# STM32WB55x register map
File version: 1.0
CPU: CM4 r0p1, little endian, 4 interrupt priority bits
Registers are 32-bit, read-write, reset 0x0 unless marked. A register's access mark holds for its fields unless they carry their own. Offsets are from the block's base; [hi:lo] are bit positions; {n}, {i} and the like mark numbered series; 'fields as' and 'values as' point back to an identical list.

## IWDG
Base 0x40003000
0x00 KR
  [15:0] KEY
0x04 PR
  [2:0] PR
0x08 RLR
  [11:0] RL
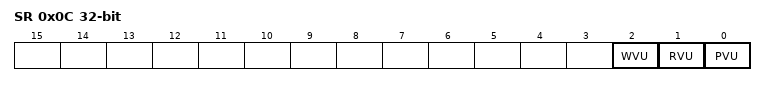
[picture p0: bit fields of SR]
0x0C SR
  [2] WVU, [1] RVU, [0] PVU
0x10 WINR
  [11:0] WIN

## WWDG
Base 0x40002C00
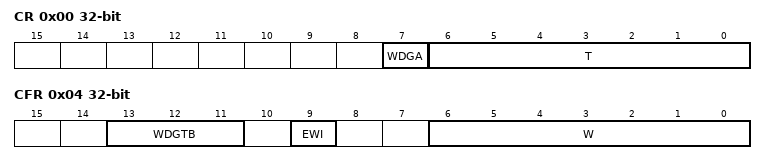
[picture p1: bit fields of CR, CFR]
0x00 CR
  [7] WDGA, [6:0] T
0x04 CFR
  [13:11] WDGTB, [9] EWI, [6:0] W
0x08 SR
  [0] EWIF

## USB_FS
Base 0x40006800
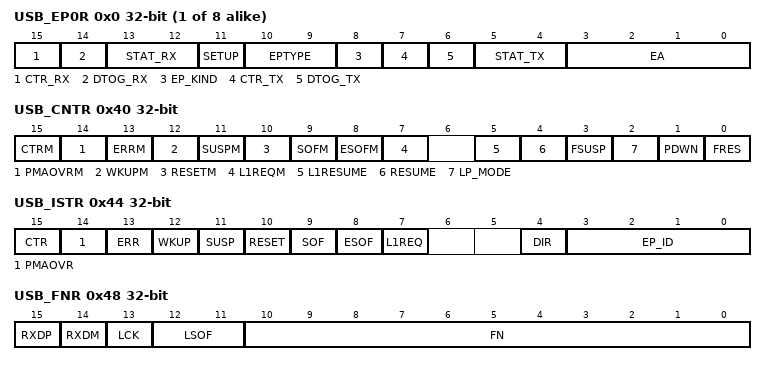
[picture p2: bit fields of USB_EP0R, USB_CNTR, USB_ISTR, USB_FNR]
{0x0+4i} USB_EP{i}R (i=0..7)
  [15] CTR_RX, [14] DTOG_RX, [13:12] STAT_RX, [11] SETUP, [10:9] EPTYPE, [8] EP_KIND, [7] CTR_TX, [6] DTOG_TX, [5:4] STAT_TX, [3:0] EA
0x40 USB_CNTR
  [15] CTRM, [14] PMAOVRM, [13] ERRM, [12] WKUPM, [11] SUSPM, [10] RESETM, [9] SOFM, [8] ESOFM, [7] L1REQM, [5] L1RESUME, [4] RESUME, [3] FSUSP, [2] LP_MODE, [1] PDWN, [0] FRES
0x44 USB_ISTR
  [15] CTR, [14] PMAOVR, [13] ERR, [12] WKUP, [11] SUSP, [10] RESET, [9] SOF, [8] ESOF, [7] L1REQ, [4] DIR, [3:0] EP_ID
0x48 USB_FNR
  [15] RXDP, [14] RXDM, [13] LCK, [12:11] LSOF, [10:0] FN
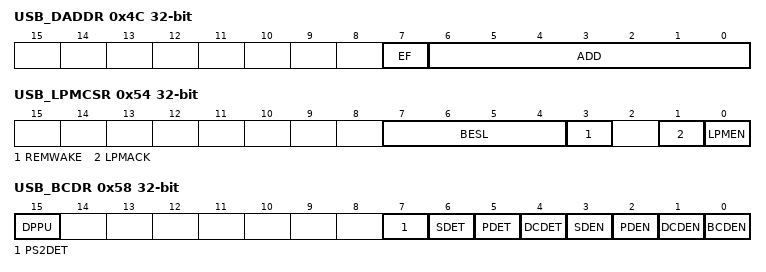
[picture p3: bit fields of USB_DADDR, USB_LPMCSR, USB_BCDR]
0x4C USB_DADDR
  [7] EF, [6:0] ADD
0x50 USB_BTABLE
  [15:3] BTABLE
0x54 USB_LPMCSR
  [7:4] BESL, [3] REMWAKE, [1] LPMACK, [0] LPMEN
0x58 USB_BCDR
  [15] DPPU, [7] PS2DET, [6] SDET, [5] PDET, [4] DCDET, [3] SDEN, [2] PDEN, [1] DCDEN, [0] BCDEN

## USART1
Base 0x40013800
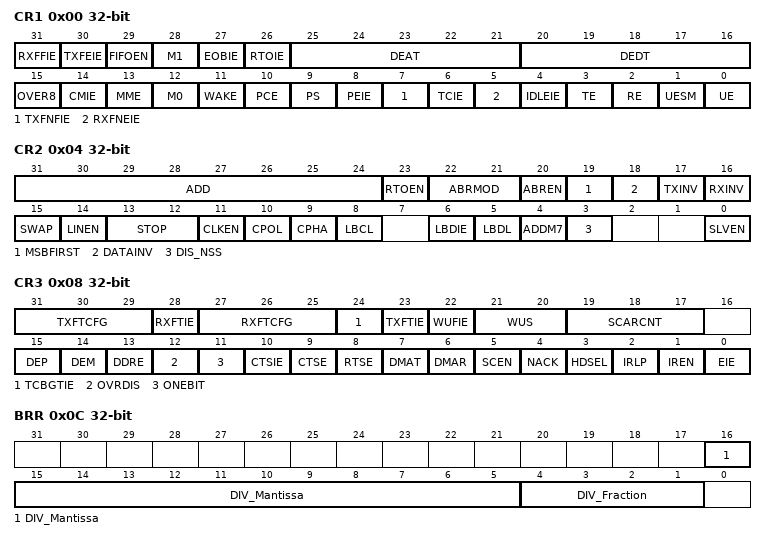
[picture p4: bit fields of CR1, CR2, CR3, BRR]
0x00 CR1
  [31] RXFFIE, [30] TXFEIE, [29] FIFOEN, [28] M1, [27] EOBIE, [26] RTOIE, [25:21] DEAT, [20:16] DEDT, [15] OVER8, [14] CMIE, [13] MME, [12] M0, [11] WAKE, [10] PCE, [9] PS, [8] PEIE, [7] TXFNFIE, [6] TCIE, [5] RXFNEIE, [4] IDLEIE, [3] TE, [2] RE, [1] UESM, [0] UE
0x04 CR2
  [31:24] ADD, [23] RTOEN, [22:21] ABRMOD, [20] ABREN, [19] MSBFIRST, [18] DATAINV, [17] TXINV, [16] RXINV, [15] SWAP, [14] LINEN, [13:12] STOP, [11] CLKEN, [10] CPOL, [9] CPHA, [8] LBCL, [6] LBDIE, [5] LBDL, [4] ADDM7, [3] DIS_NSS, [0] SLVEN
0x08 CR3
  [31:29] TXFTCFG, [28] RXFTIE, [27:25] RXFTCFG, [24] TCBGTIE, [23] TXFTIE, [22] WUFIE, [21:20] WUS, [19:17] SCARCNT, [15] DEP, [14] DEM, [13] DDRE, [12] OVRDIS, [11] ONEBIT, [10] CTSIE, [9] CTSE, [8] RTSE, [7] DMAT, [6] DMAR, [5] SCEN, [4] NACK, [3] HDSEL, [2] IRLP, [1] IREN, [0] EIE
0x0C BRR
  [16:5] DIV_Mantissa, [4:1] DIV_Fraction
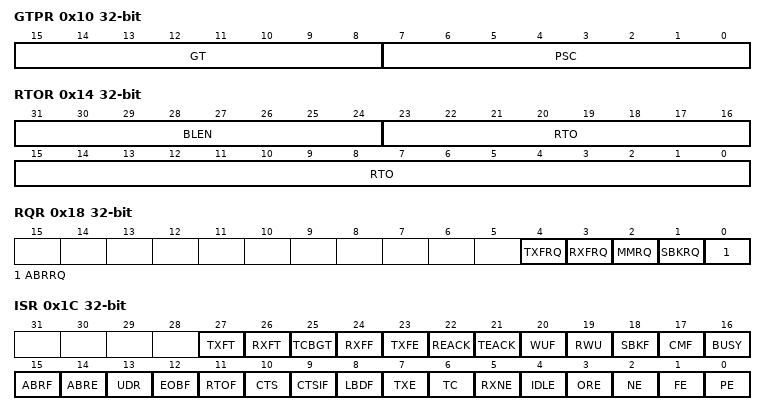
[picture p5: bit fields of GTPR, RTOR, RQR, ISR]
0x10 GTPR
  [15:8] GT, [7:0] PSC
0x14 RTOR
  [31:24] BLEN, [23:0] RTO
0x18 RQR
  [4] TXFRQ, [3] RXFRQ, [2] MMRQ, [1] SBKRQ, [0] ABRRQ
0x1C ISR
  [27] TXFT, [26] RXFT, [25] TCBGT, [24] RXFF, [23] TXFE, [22] REACK, [21] TEACK, [20] WUF, [19] RWU, [18] SBKF, [17] CMF, [16] BUSY, [15] ABRF, [14] ABRE, [13] UDR, [12] EOBF, [11] RTOF, [10] CTS, [9] CTSIF, [8] LBDF, [7] TXE, [6] TC, [5] RXNE, [4] IDLE, [3] ORE, [2] NE, [1] FE, [0] PE
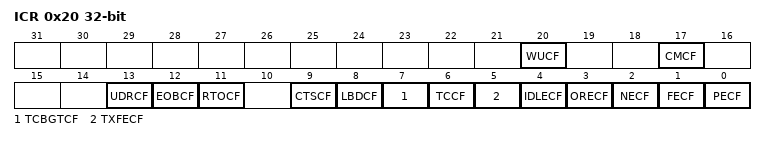
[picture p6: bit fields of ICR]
0x20 ICR
  [20] WUCF, [17] CMCF, [13] UDRCF, [12] EOBCF, [11] RTOCF, [9] CTSCF, [8] LBDCF, [7] TCBGTCF, [6] TCCF, [5] TXFECF, [4] IDLECF, [3] ORECF, [2] NECF, [1] FECF, [0] PECF
0x24 RDR
  [8:0] RDR
0x28 TDR
  [8:0] TDR
0x2C PRESC
  [3:0] PRESCALER

## TSC
Base 0x40024000
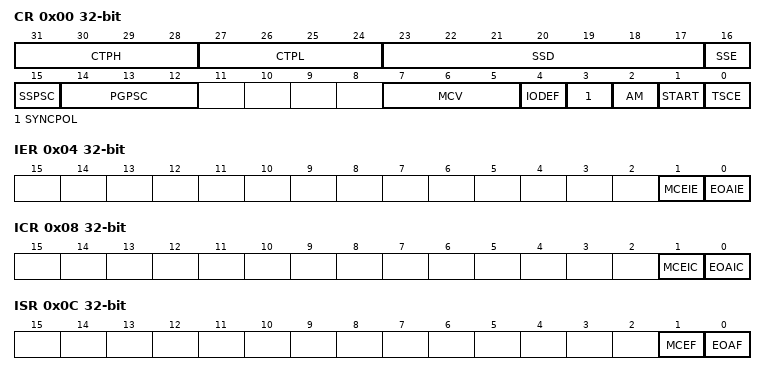
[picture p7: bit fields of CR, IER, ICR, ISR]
0x00 CR
  [31:28] CTPH, [27:24] CTPL, [23:17] SSD, [16] SSE, [15] SSPSC, [14:12] PGPSC, [7:5] MCV, [4] IODEF, [3] SYNCPOL, [2] AM, [1] START, [0] TSCE
0x04 IER
  [1] MCEIE, [0] EOAIE
0x08 ICR
  [1] MCEIC, [0] EOAIC
0x0C ISR
  [1] MCEF, [0] EOAF
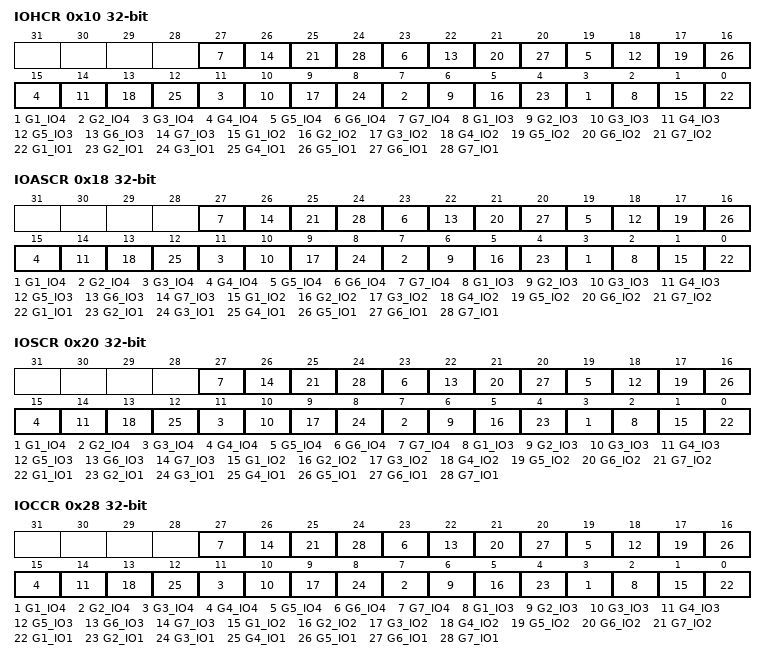
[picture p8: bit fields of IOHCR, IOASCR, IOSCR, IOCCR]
0x10 IOHCR
  [4n-1] G{n}_IO4 (n=1..7), [4n-2] G{n}_IO3 (n=1..7), [4n-3] G{n}_IO2 (n=1..7), [4n-4] G{n}_IO1 (n=1..7)
0x18 IOASCR
  fields as IOHCR
0x20 IOSCR
  fields as IOHCR
0x28 IOCCR
  fields as IOHCR
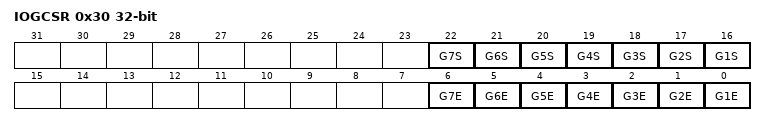
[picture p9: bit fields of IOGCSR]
0x30 IOGCSR
  [n+15] G{n}S (n=1..7), [n-1] G{n}E (n=1..7)
{0x30+4i} IOG{i}CR (i=1..7)
  [13:0] CNT

## RNG
Base 0x58001000
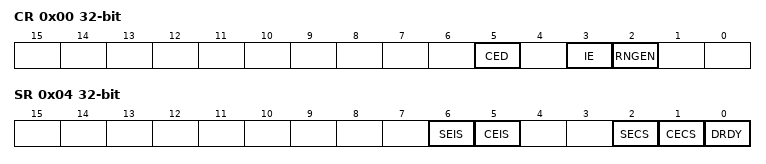
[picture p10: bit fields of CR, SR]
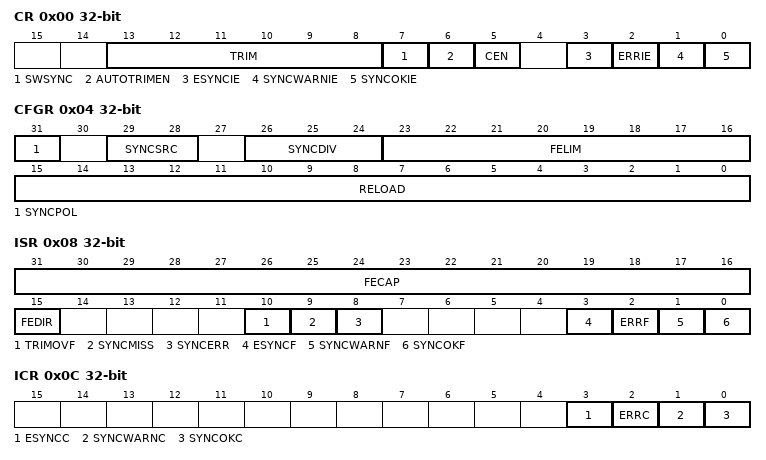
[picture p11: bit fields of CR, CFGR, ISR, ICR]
0x00 CR
  [5] CED, [3] IE, [2] RNGEN
0x04 SR
  [6] SEIS, [5] CEIS, [2] SECS, [1] CECS, [0] DRDY
0x08 DR
  [31:0] RNDATA

## CRS
Base 0x40006000
0x00 CR
  [13:8] TRIM, [7] SWSYNC, [6] AUTOTRIMEN, [5] CEN, [3] ESYNCIE, [2] ERRIE, [1] SYNCWARNIE, [0] SYNCOKIE
0x04 CFGR
  [31] SYNCPOL, [29:28] SYNCSRC, [26:24] SYNCDIV, [23:16] FELIM, [15:0] RELOAD
0x08 ISR
  [31:16] FECAP, [15] FEDIR, [10] TRIMOVF, [9] SYNCMISS, [8] SYNCERR, [3] ESYNCF, [2] ERRF, [1] SYNCWARNF, [0] SYNCOKF
0x0C ICR
  [3] ESYNCC, [2] ERRC, [1] SYNCWARNC, [0] SYNCOKC
